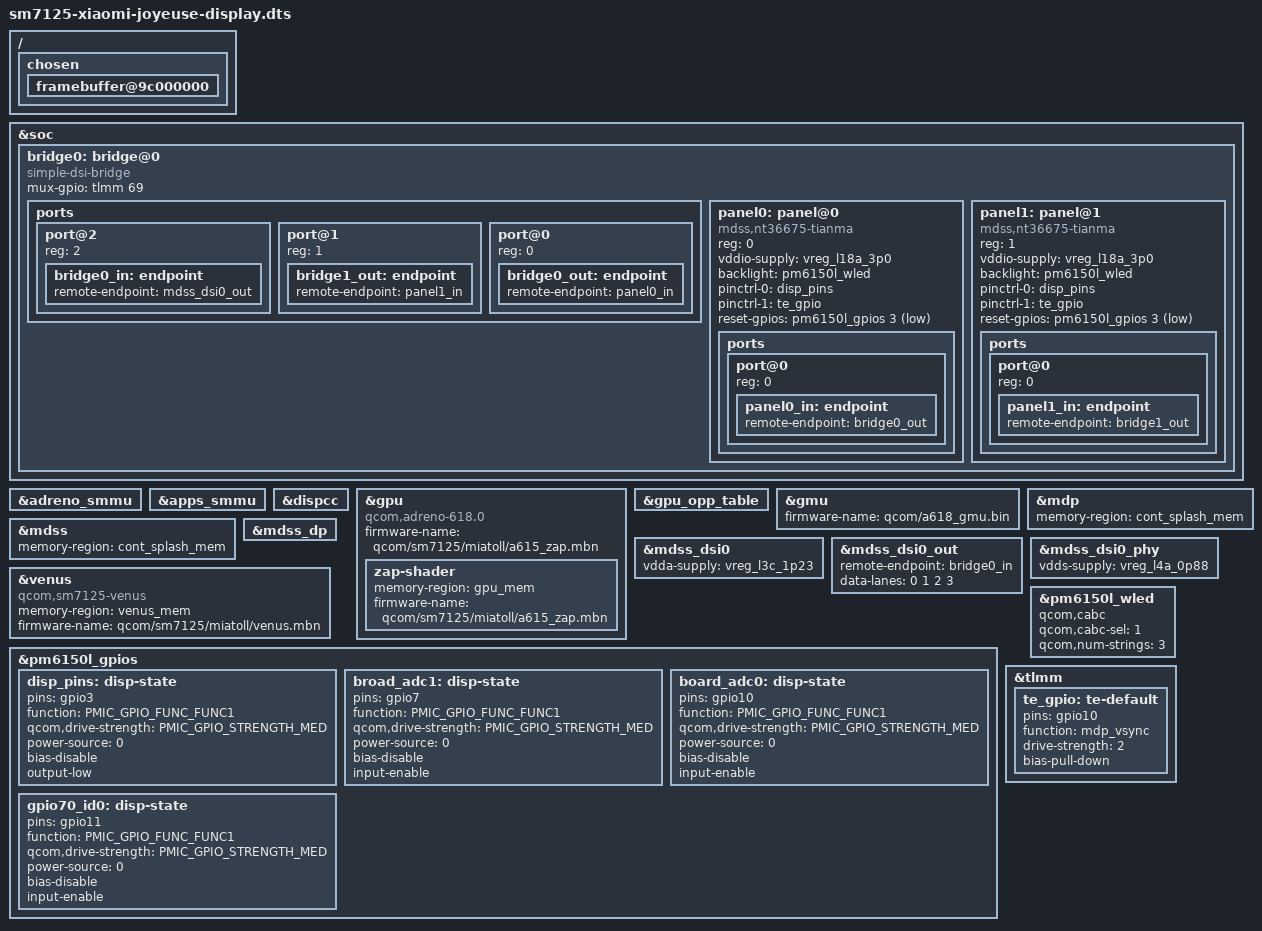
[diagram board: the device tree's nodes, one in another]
// SPDX-License-Identifier: (GPL-2.0+ OR MIT)

#ifndef SM7125_XIAOMI_JOYEUSE_DISPLAY_DTS
#define SM7125_XIAOMI_JOYEUSE_DISPLAY_DTS

#include <dt-bindings/pinctrl/qcom,pmic-gpio.h>
#include "sm7125-xiaomi-joyeuse.dts"

/* somehow added this can make AOSP boots into UI 
 * looks like the simple_drm->freedereno_drm  transition 
 * is not very fluid. Remove format property should do.
 */
/ {
        chosen {
                framebuffer@9c000000 {
			/delete-property/ format;
		};
	};
};

/*
 * since under msm dsi_host node, mdss driver wont probe child node
 * so need to move to soc node
 */
&soc {
	bridge0: bridge@0 {
	};
};

&adreno_smmu {
        status = "okay";
};

&apps_smmu {
        status = "okay";
};

&dispcc {
	status = "okay";
};

&gpu {
	compatible = "qcom,adreno-618.0", "qcom,adreno";
	firmware-name = "qcom/sm7125/miatoll/a615_zap.mbn";

	status = "okay";

	zap-shader {
			memory-region = <&gpu_mem>;
			firmware-name = "qcom/sm7125/miatoll/a615_zap.mbn";
	};
};

&gpu_opp_table {
	/* those are too high freq */
	/delete-node/ opp-825000000;
	/delete-node/ opp-800000000;
        /delete-node/ opp-650000000;

	/* those are too slow */
//        /delete-node/ opp-430000000 ;
        /delete-node/ opp-355000000 ;
        /delete-node/ opp-267000000 ;
        /delete-node/ opp-180000000 ;
};

&gmu {
	firmware-name = "qcom/a618_gmu.bin";
	status = "okay";
};

&mdp {
	// TODO: check if mdss or mdp hold this memory
	/* there was a handover problem happened to mdss probe */
	/* it was due to mdss not reset so access reserved memory issue */
	memory-region = <&cont_splash_mem>;

	status = "okay";
};

&mdss {
	// TODO: check if mdss or mdp hold this memory
	memory-region = <&cont_splash_mem>;

	status = "okay";
};

&mdss_dp {
        status = "okay";
};

&mdss_dsi0 {
	vdda-supply = <&vreg_l3c_1p23>;
	status = "okay";
};

&mdss_dsi0_out {
	remote-endpoint = <&bridge0_in>;
	data-lanes = <0 1 2 3>;

	status = "okay";
};

&mdss_dsi0_phy {
	vdds-supply = <&vreg_l4a_0p88>;

	status = "okay";
};

&bridge0 {
        #address-cells = <1>;
        #size-cells = <0>;
//	#gpio-cells = <1>;

        compatible = "simple-dsi-bridge", "simple,dsi-bridge";

	/* borrow from mmc sense-data pin */
	mux-gpio = <&tlmm 69 GPIO_ACTIVE_HIGH>;

	status = "okay";

        ports {
        	#address-cells = <1>;
	        #size-cells = <0>;

		/* numbering is flexible */
                port@2 {
                        reg = <2>;
                        bridge0_in: endpoint {
                                remote-endpoint = <&mdss_dsi0_out>;
                        };
                };

                port@1 {
                        reg = <1>;
                        bridge1_out: endpoint {
                                remote-endpoint = <&panel1_in>;
                        };
                };

                port@0 {
                        reg = <0>;
                        bridge0_out: endpoint {
                                remote-endpoint = <&panel0_in>;
                        };
                };
        };

        panel0: panel@0 {
        };

        panel1: panel@1 {
        };

};

&panel0 {
        #address-cells = <1>;
        #size-cells = <0>;

        compatible = "mdss,nt36675-tianma", /* "mdss,ft8756-huaxing", */
                        "mdss,nt36675-tianma-fhd", "novatek,nt36675-tianma";

        reg = <0>;
        vddio-supply = <&vreg_l18a_3p0>;

        backlight = <&pm6150l_wled>;

        pinctrl-names = "default", "te_pin"; //TODO: need to figure out how to handle te_pin
        pinctrl-0 = <&disp_pins>;
        pinctrl-1 = <&te_gpio>;

        /* according to panel-nt36675-tianma.c this gpio is finally set to low */
        reset-gpios = <&pm6150l_gpios 3 GPIO_ACTIVE_LOW>;
        //disp-te-gpio = <&tlmm 10 GPIO_ACTIVE_LOW>;

	/* even enabled, proxy bridge driver will enumerate with gpio pin */
        status = "okay";

        ports {
                #address-cells = <1>;
                #size-cells = <0>;
                port@0 {
                        reg = <0>;
                        panel0_in: endpoint {
                                remote-endpoint = <&bridge0_out>;
                        };
                };
        };
};

&panel1 {
        #address-cells = <1>;
        #size-cells = <0>;

//	compatible = "mdss,ft8756-huaxing";
        compatible = "mdss,nt36675-tianma", /* "mdss,ft8756-huaxing", */
                        "mdss,nt36675-tianma-fhd", "novatek,nt36675-tianma";

	reg = <1>;
	
	/* TODO: check vreg l3c/l3a */
	//vdda-supply = <&vreg_l3c_1p23>; //from downstream, need to double check
	//vdd3p3-supply = <&vreg_l18a_3p0>;
	//vddio-supply = <&vreg_l13a_1p8>; //from sm7150-xiaomi-common.dtsi
	vddio-supply = <&vreg_l18a_3p0>;

#if 0
	/* 
		display_sde.dtsi
			vddio-supply = <&L13A>;
			vdda-3p3-supply = <&L18A>;
		---
		cust-atoll-sde-display.dtsi
			/delete-property/ vdda-3p3-supply;

		        vddio-supply = <&L18A>;
	*/

	lab-supply = <&lab>;
	ibb-supply = <&ibb>;
#endif
	backlight = <&pm6150l_wled>;

	pinctrl-names = "default", "te_pin"; //TODO: need to figure out how to handle te_pin
	pinctrl-0 = <&disp_pins>;
        pinctrl-1 = <&te_gpio>;

	/* according to panel-nt36675-tianma.c this gpio is finally set to low */
	reset-gpios = <&pm6150l_gpios 3 GPIO_ACTIVE_LOW>;
	//disp-te-gpio = <&tlmm 10 GPIO_ACTIVE_LOW>;

	status = "okay";

	ports {
		#address-cells = <1>;
		#size-cells = <0>;
		port@0 {
			reg = <0>;
			panel1_in: endpoint {
				remote-endpoint = <&bridge1_out>;
			};
		};
	};
};

&venus {
	compatible = "qcom,sm7125-venus", "qcom,sc7180-venus";
	memory-region = <&venus_mem>;
	firmware-name = "qcom/sm7125/miatoll/venus.mbn";

	status = "okay";
};

/* PINCTRL - additions to nodes defined in sc7180.dtsi */
&pm6150l_gpios {
	disp_pins: disp-state {
		pins = "gpio3";
		function = PMIC_GPIO_FUNC_FUNC1;
		qcom,drive-strength = <PMIC_GPIO_STRENGTH_MED>;
		power-source = <0>;
		bias-disable;
		output-low;
	};

	/* board id */
        broad_adc1: disp-state {
                pins = "gpio7";
                function = PMIC_GPIO_FUNC_FUNC1;
                qcom,drive-strength = <PMIC_GPIO_STRENGTH_MED>;
                power-source = <0>;
                bias-disable;
		input-enable;
        };

	/* board id */
        board_adc0: disp-state {
                pins = "gpio10";
                function = PMIC_GPIO_FUNC_FUNC1;
                qcom,drive-strength = <PMIC_GPIO_STRENGTH_MED>;
                power-source = <0>;
                bias-disable;
		input-enable;
        };

	/* board id */
        gpio70_id0: disp-state {
                pins = "gpio11";
                function = PMIC_GPIO_FUNC_FUNC1;
                qcom,drive-strength = <PMIC_GPIO_STRENGTH_MED>;
                power-source = <0>;
                bias-disable;
		input-enable;
        };
};

&pm6150l_wled {
	qcom,cabc;
	qcom,cabc-sel = <1>;
	qcom,num-strings = <3>;

	status = "okay";
};

&tlmm {
        te_gpio: te-default {
                pins = "gpio10";
                function = "mdp_vsync";
                drive-strength = <2>;   /* 2 mA */
                bias-pull-down;         /* PULL DOWN */
        };
};

#endif
